# ATSAM4SDxC register map
Vendor: Atmel; Series: SAM4S; File version: 0
Atmel ATSAM4SDxC Microcontroller
CPU: CM4 r0p1, selectable endian, MPU, no FPU, 4 interrupt priority bits
Registers are 32-bit, read-write, reset 0x0 unless marked. A register's access mark holds for its fields unless they carry their own. Offsets are from the block's base; lines under a group give offsets from that group; [hi:lo] are bit positions; {n}, {i} and the like mark numbered series; 'fields as' and 'values as' point back to an identical list; <NAME> marks a mode.

## Memory map
0x40000000 HSMCI size 0x4000 — High Speed MultiMedia Card Interface
0x40004000 SSC size 0x4000 — Synchronous Serial Controller
0x40008000 SPI size 0x4000 — Serial Peripheral Interface
0x4000D000 MPU size 0x830 — Memory Protection Unit (MPU)
0x40010000 TC0 size 0x4000 — Timer Counter 0
0x40014000 TC1 size 0x4000 — Timer Counter 1
0x40018000 TWI0 size 0x4000 — Two-wire Interface 0
0x4001C000 TWI1 size 0x4000 — Two-wire Interface 1
0x40020000 PWM size 0x4000 — Pulse Width Modulation Controller
0x40024000 USART0 size 0x4000 — Universal Synchronous Asynchronous Receiver Transmitter 0
0x40028000 USART1 size 0x4000 — Universal Synchronous Asynchronous Receiver Transmitter 1
0x40034000 UDP size 0x4000 — USB Device Port
0x40038000 ADC size 0x4000 — Analog-to-Digital Converter
0x4003C000 DACC size 0x4000 — Digital-to-Analog Converter Controller
0x40040000 ACC size 0x4000 — Analog Comparator Controller
0x40044000 CRCCU size 0x4000 — Cyclic Redundancy Check Calculation Unit
0x4007C000 CMCC size 0x4000 — Cortex M Cache Controller
0x400E0000 SMC size 0x200 — Static Memory Controller
0x400E0200 MATRIX size 0x200 — AHB Bus Matrix
0x400E0400 PMC size 0x140 — Power Management Controller
0x400E0600 UART0 size 0x128 — Universal Asynchronous Receiver Transmitter 0
0x400E0740 CHIPID size 0x200 — Chip Identifier
0x400E0800 UART1 size 0x128 — Universal Asynchronous Receiver Transmitter 1
0x400E0A00 EFC0 size 0x200 — Embedded Flash Controller 0
0x400E0C00 EFC1 size 0x200 — Embedded Flash Controller 1
0x400E0E00 PIOA size 0x200 — Parallel Input/Output Controller A
0x400E1000 PIOB size 0x200 — Parallel Input/Output Controller B
0x400E1200 PIOC size 0x200 — Parallel Input/Output Controller C
0x400E1400 RSTC size 0x200 — Reset Controller
0x400E1410 SUPC size 0x200 — Supply Controller
0x400E1430 RTT size 0x200 — Real-time Timer
0x400E1450 WDT size 0x200 — Watchdog Timer
0x400E1460 RTC size 0x200 — Real-time Clock
0x400E1490 GPBR size 0x200 — General Purpose Backup Registers
0xE000E000 SCB blocks up to offset 0xD40 — System Control Block (SCB)
0xE000E010 SYST size 0x10 — System timer, SysTick
0xE000E100 NVIC size 0xE04 — Nested Vectored Interrupt Controller (NVIC)

## Interrupts
3 INT_Hard_Fault (SCB)
4 INT_Mem_Manage_Fault (SCB)
5 INT_Bus_Fault (SCB)
5 PMC
6 EFC0
6 INT_Usage_Fault (SCB)
7 EFC1
8 UART0
9 UART1
11 INT_SVCall (SCB)
11 PIOA
12 PIOB
13 PIOC
14 INT_PendableSrvReq (SCB)
14 USART0
15 INT_SysTick (SYST)
15 USART1
18 HSMCI
19 TWI0
20 TWI1
21 SPI
22 SSC
23 TC0
24 TC1 (TC0)
25 TC2 (TC0)
26 TC3 (TC1)
27 TC4 (TC1)
28 TC5 (TC1)
29 ADC
30 DACC
31 PWM
32 CRCCU
33 ACC
34 UDP

## ACC — Analog Comparator Controller
Base 0x40040000; register names take the prefix ACC_
0x00 CR wo reset not defined — Control Register
  [0] SWRST — Software Reset
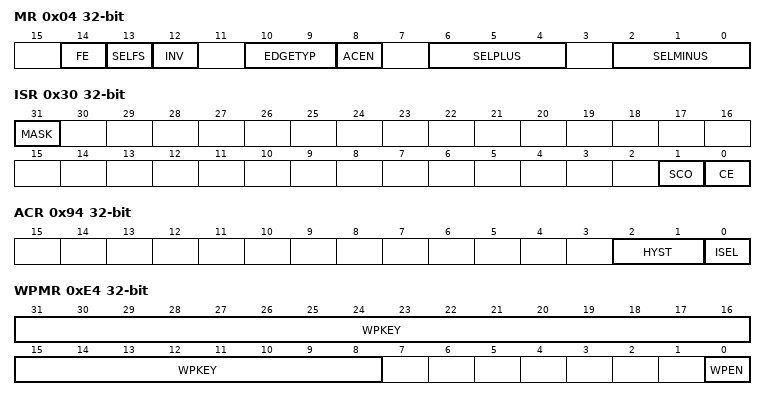
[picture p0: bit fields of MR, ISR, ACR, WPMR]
0x04 MR — Mode Register
  [14] FE — Fault Enable
    0=DIS (The FAULT output is tied to 0.); 1=EN (The FAULT output is driven by the signal defined by SELFS.)
  [13] SELFS — Selection Of Fault Source
    0=CF (The CF flag is used to drive the FAULT output.); 1=OUTPUT (The output of the analog comparator flag is used to drive the FAULT output.)
  [12] INV — Invert Comparator Output
    0=DIS (Analog comparator output is directly processed.); 1=EN (Analog comparator output is inverted prior to being processed.)
  [10:9] EDGETYP — Edge Type
    0=RISING (Only rising edge of comparator output); 1=FALLING (Falling edge of comparator output); 2=ANY (Any edge of comparator output)
  [8] ACEN — Analog Comparator Enable
    0=DIS (Analog comparator disabled.); 1=EN (Analog comparator enabled.)
  [6:4] SELPLUS — Selection For Plus Comparator Input
    {v}=AD{v} (Select AD{v}) (v=0..7)
  [2:0] SELMINUS — Selection for Minus Comparator Input
    0=TS (Select TS); 1=ADVREF (Select ADVREF); 2=DAC0 (Select DAC0); 3=DAC1 (Select DAC1); {v}=AD{v-4} (Select AD{v-4}) (v=4..7)
0x24 IER wo reset not defined — Interrupt Enable Register
  [0] CE — Comparison Edge
0x28 IDR wo reset not defined — Interrupt Disable Register
  [0] CE — Comparison Edge
0x2C IMR ro — Interrupt Mask Register
  [0] CE — Comparison Edge
0x30 ISR ro — Interrupt Status Register
  [31] MASK — Flag Mask
  [1] SCO — Synchronized Comparator Output
  [0] CE — Comparison Edge
0x94 ACR — Analog Control Register
  [2:1] HYST — Hysteresis Selection
  [0] ISEL — Current Selection
    0=LOPW (Low-power option.); 1=HISP (High-speed option.)
0xE4 WPMR — Write Protection Mode Register
  [31:8] WPKEY — Write Protection Key
    0x414343=PASSWD (Writing any other value in this field aborts the write operation of the WPEN bit.Always reads as 0.)
  [0] WPEN — Write Protection Enable
0xE8 WPSR ro — Write Protection Status Register
  [0] WPVS — Write Protection Violation Status

## Notices in the file
SAM Software Package License
Copyright (c) 2014, Atmel Corporation
All rights reserved.
Redistribution and use in source and binary forms, with or without
modification, are permitted provided that the following condition is met:
- Redistributions of source code must retain the above copyright notice,
this list of conditions and the disclaimer below.
Atmel's name may not be used to endorse or promote products derived from
this software without specific prior written permission.
DISCLAIMER:  THIS SOFTWARE IS PROVIDED BY ATMEL "AS IS" AND ANY EXPRESS OR
IMPLIED WARRANTIES, INCLUDING, BUT NOT LIMITED TO, THE IMPLIED WARRANTIES OF
MERCHANTABILITY, FITNESS FOR A PARTICULAR PURPOSE AND NON-INFRINGEMENT ARE
DISCLAIMED. IN NO EVENT SHALL ATMEL BE LIABLE FOR ANY DIRECT, INDIRECT,
INCIDENTAL, SPECIAL, EXEMPLARY, OR CONSEQUENTIAL DAMAGES (INCLUDING, BUT NOT
LIMITED TO, PROCUREMENT OF SUBSTITUTE GOODS OR SERVICES; LOSS OF USE, DATA,
OR PROFITS; OR BUSINESS INTERRUPTION) HOWEVER CAUSED AND ON ANY THEORY OF
LIABILITY, WHETHER IN CONTRACT, STRICT LIABILITY, OR TORT (INCLUDING
NEGLIGENCE OR OTHERWISE) ARISING IN ANY WAY OUT OF THE USE OF THIS SOFTWARE,
EVEN IF ADVISED OF THE POSSIBILITY OF SUCH DAMAGE.
